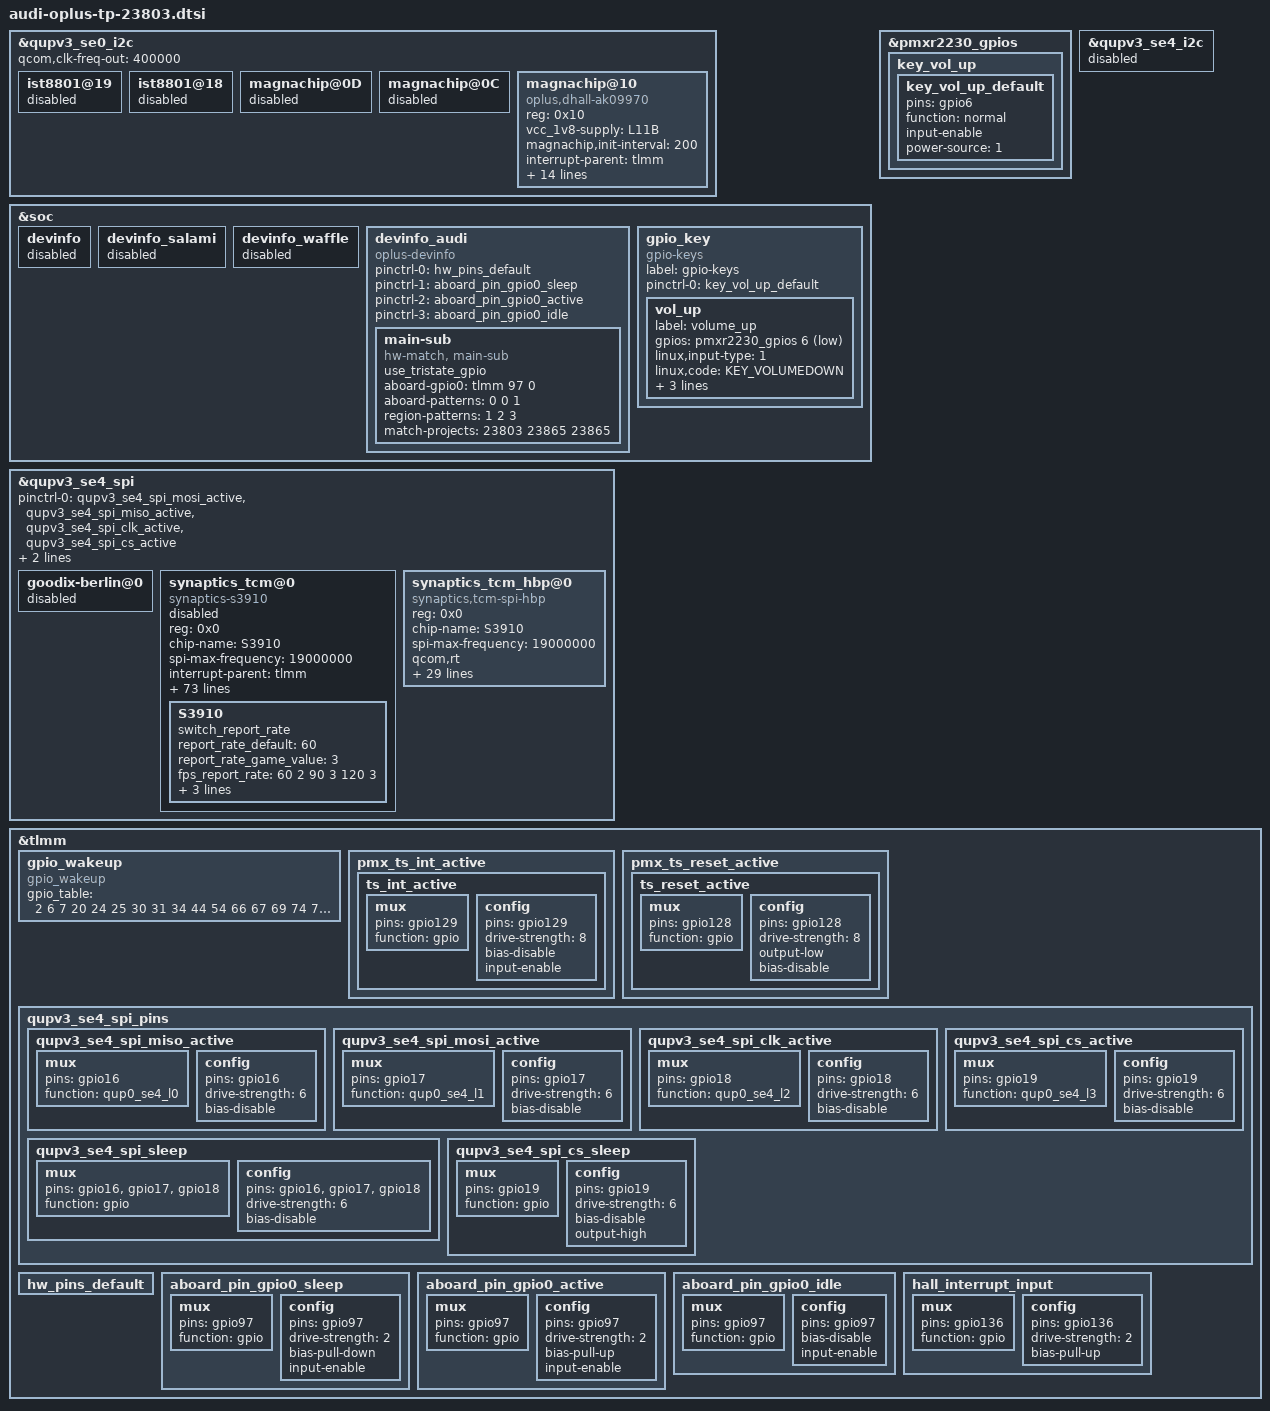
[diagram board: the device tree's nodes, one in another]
&qupv3_se0_i2c {
	status = "ok";
	qcom,clk-freq-out = <400000>;
	/delete-node/ magnachip@0D;
	/delete-node/ magnachip@0C;
	/delete-node/ ist8801@19;
	/delete-node/ ist8801@18;

	ist8801@19 {
		status = "disabled";
	};
	ist8801@18 {
		status = "disabled";
	};
	magnachip@0D {
		status = "disabled";
	};
	magnachip@0C {
		status = "disabled";
	};

	magnachip@10 {
		compatible = "oplus,dhall-ak09970";
		reg = <0x10>;
		vcc_1v8-supply = <&L11B>;
		magnachip,init-interval = <200>;
		interrupt-parent = <&tlmm>;
		interrups = <136 0x02>;
		threeaxis_hall_support;
		dhall,irq-gpio = <&tlmm 136 0x2008>;
		pinctrl-names = "hall_interrupt_input";
		pinctrl-0 = <&hall_interrupt_input>;

		turn_upside_down;
		interf_stable_limit = <700 700 700>;
		interf_judege_limit = <4000 2000>;
		interf_up_tolen = <2500 2000 2500 2000>;
		interf_mid_tolen = <2500 2000 2500 2000>;
		interf_down_tolen = <2500 2000 2500 2000>;
		position_judge_tolen = <3300 3300>;
		default_position_xtolen = <2500 2500>;

		exception_upload_support;
		health_monitor_support;
	};
};

&soc {

	devinfo {
		status = "disabled";
	};

	devinfo_salami {
		status = "disabled";
	};

	devinfo_waffle {
		status = "disabled";
	};

	devinfo_audi {
		compatible = "oplus-devinfo";
		pinctrl-names = "default", "sleep", "active", "idle";
		pinctrl-0 = <&hw_pins_default>;
		pinctrl-1 = <&aboard_pin_gpio0_sleep>;
		pinctrl-2 = <&aboard_pin_gpio0_active>;
		pinctrl-3 = <&aboard_pin_gpio0_idle>;

		main-sub {
			compatible = "hw-match, main-sub";
			use_tristate_gpio;
			aboard-gpio0 = <&tlmm 97 0>;
			aboard-patterns = <0 0 1>;	/*0[high-resistance] 1[pull-down] 2[pull-up]*/
			/*region id*/
			region-patterns = <1 2 3>;
			/*main board*/
			match-projects = <23803 23865 23865>;
		};
	};
};

&pmxr2230_gpios {
	/delete-node/ key_vol_up;
	key_vol_up {
		key_vol_up_default: key_vol_up_default {
			pins = "gpio6";
			function = "normal";
			input-enable;
			power-source = <1>;
		};
	};
};

&qupv3_se4_i2c {
	status = "disabled";
};

&qupv3_se4_spi{
	/delete-property/ pinctrl-0;
	/delete-property/ pinctrl-1;
	pinctrl-0 = <&qupv3_se4_spi_mosi_active>, <&qupv3_se4_spi_miso_active>,
				<&qupv3_se4_spi_clk_active>, <&qupv3_se4_spi_cs_active>;
	pinctrl-1 = <&qupv3_se4_spi_sleep>, <&qupv3_se4_spi_cs_sleep>;
};

&qupv3_se4_spi {
	status = "ok";

	goodix-berlin@0 {
		status = "disabled";
	};

	synaptics_tcm@0{
		compatible = "synaptics-s3910";
		reg = <0x0>;
		chip-name = "S3910";
		status = "disabled";
		spi-max-frequency = <19000000>;

		/* Interrupt && Irq-gpio */
		interrupt-parent = <&tlmm>;
		interrupts = <129 0x2008>;

		/* Power Config */
		vdd_2v8-supply = <&L22B>;
		vcc_1v8-supply = <&L5M>;
		vdd_2v8_volt = <3008000>;

		/* Other HW Resource */
		irq-gpio = <&tlmm 129 0x2008>;
		reset-gpio = <&tlmm 128 0x1>;
		pinctrl-names = "default";
		pinctrl-0 = <&ts_int_active &ts_reset_active>;

		touchpanel,max-num-support = <10>;
		touchpanel,tx-rx-num = <16 36>;
		earsense,tx-rx-num = <17 18>;
		touchpanel,panel-coords = <12400 27720>;
		touchpanel,display-coords = <1240 2772>;
		touchpanel,touchmajor-limit = <256 256>;
		touchpanel,int-mode = <1>; /*0: interrupt and disable, 1:interrupt and not disable*/
		touchpanel,curved-size = <45>;

		prevention,curved_screen_V2;
		prevention,grip_disable_level = <6>;
		prevention,updelay_time_ms = <30>;
		prevention,makeup_cnt_weight = <4 1 2 2 2>;
		prevention,large_corner_range = <2564 6217>;
		prevention,large_corner_judge_condition = <500 300 2194 7 7>;
		prevention,trx_reject_condition = <8 7 7>;
		prevention,trx_strict_reject_condition = <8 6 6>;
		prevention,large_judge_time_ms = <500 50 30>;
		prevention,large_exit_condition = <8 8 2>;
		prevention,single_channel_width = <320 320>;
		prevention,normal_tap_condition = <10 350>;
		prevention,long_edge_condition = <179 90 120 80>;
		prevention,long_strict_edge_condition = <160 60>;
		prevention,long_fingerhold_condition = <70 6 4 4>;
		prevention,short_edge_condition = <179 90 120 80>;
		prevention,short_strict_edge_condition = <160 60>;
		prevention,large_strict_exit_condition = <6 6>;
		prevention,top_corner_config = <464 1371 1000>;
		prevention,edge_swipe_config = <340 1130>;

		touchpanel,smooth-level = <0 1 2 4 7 9>;
		touchpanel,smooth-level-charging = <0 2 4 7 8 9>;
		touchpanel,sensitive-level = <0 70 55 40 25 10>;
		touchpanel,single-optimized-time = <8>;
		touchpanel,high-frame-rate-time = <60>;

		end_stretch_value = <480 250 16 16>;
		//touchpanel,tp_ic_type = <2>;
		panel_type = <7 7 7>;
		// type of tp_dev ,TP-SAMSUNG = 8;
		platform_support_project = <23803 23865 23866>;
		platform_support_project_dir = <23803 23803 23803>;
		platform_support_project_commandline = "default_commandline", "default_commandline", "default_commandline";

		/* SW Support Feature Control */
		black_gesture_support;
		//fw_edge_limit_support;
		pressure_report_support;
		charger_pump_support;
		game_switch_support;
		smart_gesture_support;
		fw_update_app_support;
		fingerprint_underscreen_support;
		freq_hop_simulate_support;
		report_flow_unlock_support;
		screenoff_fingerprint_info_support;
		irq_need_dev_resume_ok;
		//firmware_in_dts;
		//enable_point_auto_change;
		kernel_grip_support;
		//grip_no_driver_support;
		health_monitor_support;
		black_gesture_indep_support;
		exception_upload_support;
		sportify_aod_gesture_support;
		glove_mode_support;
		fingerprint_not_report_in_suspend;
		snr_read_support;
		//temperature_detect_support;
		palm_to_sleep_support;
		tp_data_record_support;
		skip_reinit_device_support;

		/*
		 *Virtual Key Config:
		 *1:touchpanel,button-type: <virtualkey_type  supportted_button-map>
		 *virtualkey_type:
		 *Type 1: using board_properties
		 *Type 2: using same IC (button zone&& touch zone are seprate)
		 *Type 3: using diffrent IC (button zone&& touch zone are seprate)
		 *Type 4: No need of virtual key process
		 *supportted_button-map:select|menu|home|back
		 *
		 *2:touchpanel,button-map
		 *type (X1,Y1)(X2,Y2)(X3,Y3)(Width_X,Hight_Y)--Only when button-type is 0
		 */
		touchpanel,button-type = <4>;
		touchpanel.button-TRx = <0 0>;

		S3910 {
			switch_report_rate;
			report_rate_default = <60>;
			report_rate_game_value = <3>;
			fps_report_rate = <60 2 90 3 120 3>;//1:360Hz 2:125Hz 3:240Hz
			default_gesture_mask = <8191>;
			fwupdate_bootloader = <1>;
			normal_config_version = <2>;
		};
	};

	synaptics_tcm_hbp@0{
		compatible = "synaptics,tcm-spi-hbp";
		reg = <0x0>;
		chip-name = "S3910";
		status = "okay";
		spi-max-frequency = <19000000>;
		qcom,rt;

		/* Interrupt && Irq-gpio */
		interrupt-parent = <&tlmm>;
		interrupts = <129 0x2008>;

		/* Power Config */
		vdd-supply = <&L22B>;
		vcc-supply = <&L5M>;
		synaptics,avdd-name = "vdd";
		synaptics,vdd-name = "vcc";

		/* Other HW Resource */
		synaptics,irq-gpio = <&tlmm 129 0x2008>;
		synaptics,reset-gpio = <&tlmm 128 0x1>;
		pinctrl-names = "default";
		pinctrl-0 = <&ts_int_active &ts_reset_active>;

		touchpanel,panel-coords = <19840 44352>;
		touchpanel,tx-rx-num = <16 36>;
		panel_type = <7 7 7>;
		firmware_name = "AH553";
		platform_support_project = <23803 23865 23866>;
		platform_support_project_dir = <23803 23803 23803>;
		platform_support_project_commandline = "mdss_dsi_panel_AA553_P_7_A0001_dsc_cmd", "default_commandline", "default_commandline";

		synaptics,power-on-state = <1>;
		synaptics,power-delay-ms = <200>;
		synaptics,irq-on-state = <0>;
		synaptics,reset-on-state = <0>;
		synaptics,reset-active-ms = <10>;
		synaptics,reset-delay-ms = <80>;
		synaptics,spi-mode = <0>;
		synaptics,spi-byte-delay-us = <0>;
		synaptics,spi-block-delay-us = <0>;

		/* SW Support Feature Control */
		tp_data_record_support;
	};

};

&tlmm {

	/delete-node/ pmx_ts_reset_suspend;
	/delete-node/ pmx_ts_int_suspend;
	/delete-node/ pmx_ts_release;
	/delete-node/ pmx_ts_active;

	gpio_wakeup: gpio_wakeup {
		compatible = "gpio_wakeup";
		gpio_table = <2 6 7 20 24 25 30 31 34 44 54 66 67 69 74 75 78 98 99 101 102 103 104 107 108 109 110 111 112 119 130 133 135 138 148 153 157 166 167 171>;
	};

	pmx_ts_int_active {
		ts_int_active: ts_int_active {
			mux {
				pins = "gpio129";
				function = "gpio";
			};

			config {
				pins = "gpio129";
				drive-strength = <8>;
				bias-disable;
				input-enable;
			};
		};
	};

	pmx_ts_reset_active {
		ts_reset_active: ts_reset_active {
			mux {
				pins = "gpio128";
				function = "gpio";
			};

			config {
				pins = "gpio128";
				drive-strength = <8>;
				output-low;
				bias-disable;
			};
		};
	};

	qupv3_se4_spi_pins: qupv3_se4_spi_pins {
		qupv3_se4_spi_miso_active: qupv3_se4_spi_miso_active {
			mux {
				pins = "gpio16";
				function = "qup0_se4_l0";
			};

			config {
				pins = "gpio16";
				drive-strength = <6>;
				bias-disable;
			};
		};

		qupv3_se4_spi_mosi_active: qupv3_se4_spi_mosi_active {
			mux {
				pins = "gpio17";
				function = "qup0_se4_l1";
			};

			config {
				pins = "gpio17";
				drive-strength = <6>;
				bias-disable;
			};
		};

		qupv3_se4_spi_clk_active: qupv3_se4_spi_clk_active {
			mux {
				pins = "gpio18";
				function = "qup0_se4_l2";
			};

			config {
				pins = "gpio18";
				drive-strength = <6>;
				bias-disable;
			};
		};

		qupv3_se4_spi_cs_active: qupv3_se4_spi_cs_active {
			mux {
				pins = "gpio19";
				function = "qup0_se4_l3";
			};

			config {
				pins = "gpio19";
				drive-strength = <6>;
				bias-disable;
			};
		};

		qupv3_se4_spi_sleep: qupv3_se4_spi_sleep {
			mux {
				pins = "gpio16", "gpio17",
						"gpio18";
				function = "gpio";
			};

			config {
				pins = "gpio16", "gpio17",
						"gpio18";
				drive-strength = <6>;
				bias-disable;
			};
		};

		qupv3_se4_spi_cs_sleep: qupv3_se4_spi_cs_sleep {
			mux {
				pins = "gpio19";
				function = "gpio";
			};

			config {
				pins = "gpio19";
				drive-strength = <6>;
				bias-disable;
				output-high;
			};
		};
	};

	hw_pins_default:hw_pins_default {
	};
	aboard_pin_gpio0_sleep:aboard_pin_gpio0_sleep {
		mux {
			pins = "gpio97";
			function = "gpio";
		};
		config {
			pins = "gpio97";
			drive-strength = <2>;
			bias-pull-down;
			input-enable;
		};
	};

	aboard_pin_gpio0_active:aboard_pin_gpio0_active {
		mux {
			pins = "gpio97";
			function = "gpio";
		};
		config {
			pins = "gpio97";
			drive-strength = <2>;
			bias-pull-up;
			input-enable;
		};
	};

	aboard_pin_gpio0_idle:aboard_pin_gpio0_idle {
		mux {
			pins = "gpio97";
			function = "gpio";
		};
		config {
			pins = "gpio97";
			bias-disable;
			input-enable;
		};
	};

	//#ifdef OPLUS_FEATURE_TRI_KEY
	hall_interrupt_input: hall_interrupt_input {
		mux {
			pins = "gpio136";
			function = "gpio";
		};
		config {
			pins = "gpio136";
			drive-strength = <2>;
			bias-pull-up;
		};
	};
};

&soc {
	/delete-node/ gpio_key;
	gpio_key {
		compatible = "gpio-keys";
		label = "gpio-keys";
		pinctrl-names = "default";
		pinctrl-0 = <&key_vol_up_default>;
		vol_up {
			label = "volume_up";
			gpios = <&pmxr2230_gpios 6 GPIO_ACTIVE_LOW>;
			linux,input-type = <1>;
			linux,code = <KEY_VOLUMEDOWN>;
			gpio-key,wakeup;
			debounce-interval = <32>;
			linux,can-disable;
		};
	};
};
